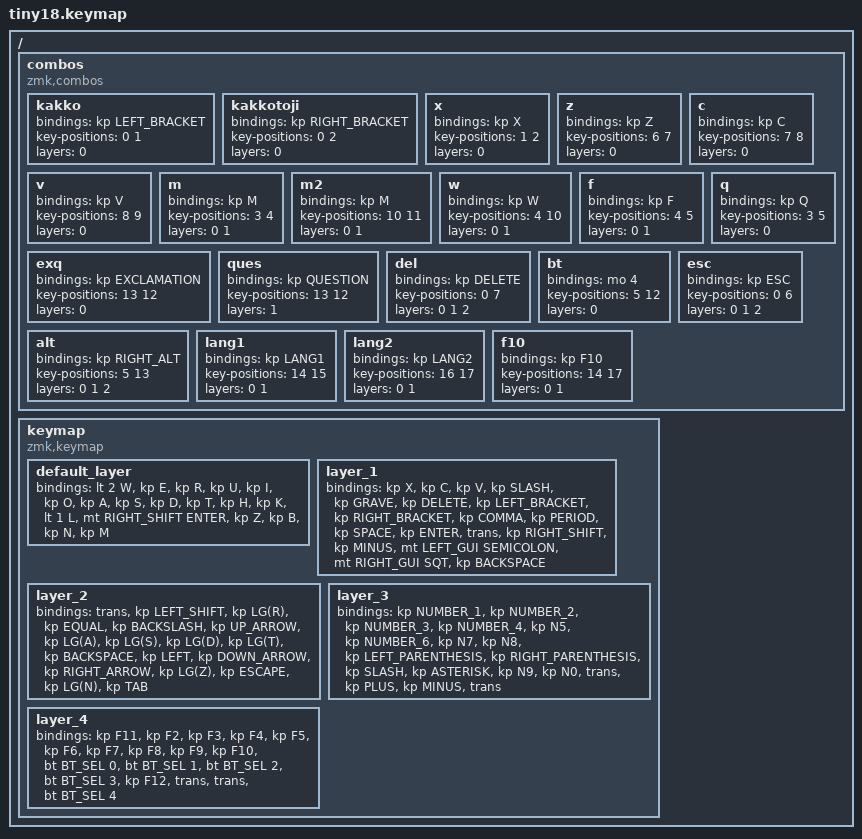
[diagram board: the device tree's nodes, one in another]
#include <input/processors.dtsi>
#include <dt-bindings/zmk/input_transform.h>
#include <zephyr/dt-bindings/input/input-event-codes.h>
#include one <behaviors.dtsi>
#include <dt-bindings/zmk/bt.h>
#include <dt-bindings/zmk/keys.h>

/ {
    combos {
        compatible = "zmk,combos";

        kakko {
            bindings = <&kp LEFT_BRACKET>;
            key-positions = <0 1>;
            layers = <0>;
        };

        kakkotoji {
            bindings = <&kp RIGHT_BRACKET>;
            key-positions = <0 2>;
            layers = <0>;
        };

        x {
            bindings = <&kp X>;
            key-positions = <1 2>;
            layers = <0>;
        };

        z {
            bindings = <&kp Z>;
            key-positions = <6 7>;
            layers = <0>;
        };

        c {
            bindings = <&kp C>;
            key-positions = <7 8>;
            layers = <0>;
        };

        v {
            bindings = <&kp V>;
            key-positions = <8 9>;
            layers = <0>;
        };

        m {
            bindings = <&kp M>;
            key-positions = <3 4>;
            layers = <0 1>;
        };

        m2 {
            bindings = <&kp M>;
            key-positions = <10 11>;
            layers = <0 1>;
        };

        w {
            bindings = <&kp W>;
            key-positions = <4 10>;
            layers = <0 1>;
        };

        f {
            bindings = <&kp F>;
            key-positions = <4 5>;
            layers = <0 1>;
        };

        q {
            bindings = <&kp Q>;
            key-positions = <3 5>;
            layers = <0>;
        };

        exq {
            bindings = <&kp EXCLAMATION>;
            key-positions = <13 12>;
            layers = <0>;
        };

        ques {
            bindings = <&kp QUESTION>;
            key-positions = <13 12>;
            layers = <1>;
        };

        del {
            bindings = <&kp DELETE>;
            key-positions = <0 7>;
            layers = <0 1 2>;
        };

        bt {
            bindings = <&mo 4>;
            key-positions = <5 12>;
            layers = <0>;
        };

        esc {
            bindings = <&kp ESC>;
            key-positions = <0 6>;
            layers = <0 1 2>;
        };

        alt {
            bindings = <&kp RIGHT_ALT>;
            key-positions = <5 13>;
            layers = <0 1 2>;
        };

        lang1 {
            bindings = <&kp LANG1>;
            key-positions = <14 15>;
            layers = <0 1>;
        };

        lang2 {
            bindings = <&kp LANG2>;
            key-positions = <16 17>;
            layers = <0 1>;
        };

        f10 {
            bindings = <&kp F10>;
            key-positions = <14 17>;
            layers = <0 1>;
        };
    };
    keymap {
        compatible = "zmk,keymap";

        default_layer {
            bindings = <
&lt 2 W  &kp E  &kp R  &kp U  &kp I  &kp O  &kp A  &kp S  &kp D  &kp T  &kp H  &kp K  &lt 1 L  &mt RIGHT_SHIFT ENTER  &kp Z  &kp B  &kp N  &kp M
            >;
        };

        layer_1 {
            bindings = <
&kp X  &kp C  &kp V  &kp SLASH  &kp GRAVE  &kp DELETE  &kp LEFT_BRACKET  &kp RIGHT_BRACKET  &kp COMMA  &kp PERIOD  &kp SPACE  &kp ENTER  &trans  &kp RIGHT_SHIFT  &kp MINUS  &mt LEFT_GUI SEMICOLON  &mt RIGHT_GUI SQT  &kp BACKSPACE
            >;
        };

        layer_2 {
            bindings = <
&trans  &kp LEFT_SHIFT  &kp LG(R)  &kp EQUAL  &kp BACKSLASH  &kp UP_ARROW  &kp LG(A)  &kp LG(S)  &kp LG(D)  &kp LG(T)  &kp BACKSPACE  &kp LEFT  &kp DOWN_ARROW  &kp RIGHT_ARROW  &kp LG(Z)  &kp ESCAPE  &kp LG(N)  &kp TAB
            >;
        };

        layer_3 {
            bindings = <
&kp NUMBER_1  &kp NUMBER_2  &kp NUMBER_3  &kp NUMBER_4  &kp N5  &kp NUMBER_6  &kp N7  &kp N8  &kp LEFT_PARENTHESIS  &kp RIGHT_PARENTHESIS  &kp SLASH  &kp ASTERISK  &kp N9  &kp N0  &trans  &kp PLUS  &kp MINUS  &trans
            >;
        };

        layer_4 {
            bindings = <
&kp F11  &kp F2  &kp F3  &kp F4  &kp F5  &kp F6  &kp F7  &kp F8  &kp F9  &kp F10  &bt BT_SEL 0  &bt BT_SEL 1  &bt BT_SEL 2  &bt BT_SEL 3  &kp F12  &trans  &trans  &bt BT_SEL 4
            >;
        };
    };
};
